VERSION ""

NS_ :

BS_:

BU_:
VAL_TABLE_ ActiveStored 1 "Active" 0 "Stored" ;
VAL_TABLE_ LN 63 "ACM" 53 "4WS" 51 "EFC" 33 "PICTO" 32 "CEAG" 31 "EMM" 30 "SPECIFIC" 27 "TA" 26 "SBL" 25 "WBZ" 24 "SCT" 20 "INFO" 17 "LCP" 15 "ZE" 13 "TELEM" 12 "DIAGNOSE" 11 "TI" 4 "DRIVE" 3 "MFA" 2 "NT01" 1 "ES" 0 "DASH" ;
VAL_TABLE_ DiagFlag 1 "Active" 0 "Not Active" ;
VAL_TABLE_ RequestID 49 "Counters and Env Vars" 23 "Read Error Memory" 20 "Clear Error Memory" ;

BO_ 3221225472 VECTOR__INDEPENDENT_SIG_MSG: 0 Vector__XXX
 SG_ Time : 0|32@1+ (1,0) [0|0] "" Vector__XXX
 SG_ Date : 0|32@1+ (1,0) [0|0] "" Vector__XXX
 SG_ OperatingHours : 0|32@1+ (1,0) [0|0] "" Vector__XXX

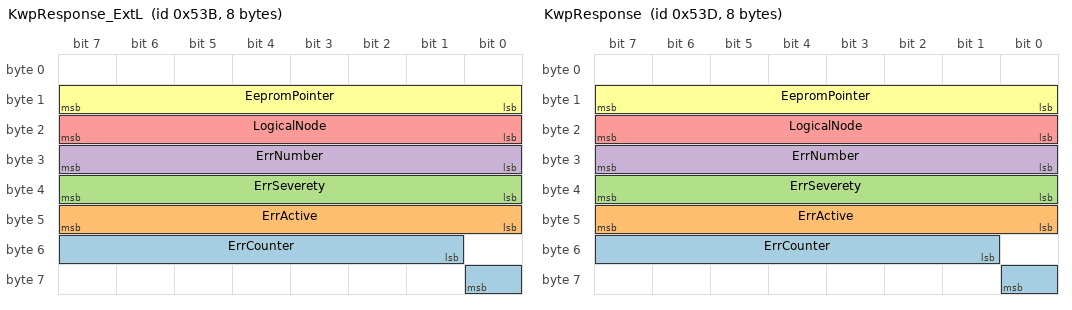
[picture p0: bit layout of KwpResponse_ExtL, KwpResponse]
BO_ 1339 KwpResponse_ExtL: 8 Vector__XXX
 SG_ ErrCounter : 49|8@1+ (1,0) [0|0] "" Vector__XXX
 SG_ ErrActive : 40|8@1+ (1,0) [0|0] "" Vector__XXX
 SG_ ErrSeverety : 32|8@1+ (1,0) [0|0] "" Vector__XXX
 SG_ ErrNumber : 24|8@1+ (1,0) [0|0] "" Vector__XXX
 SG_ LogicalNode : 16|8@1+ (1,0) [0|0] "" Vector__XXX
 SG_ EepromPointer : 8|8@1+ (1,0) [0|0] "" Vector__XXX

BO_ 1338 KwpRequest_ExtL: 4 Vector__XXX
 SG_ DiagMode : 24|8@1+ (1,0) [0|0] "" Vector__XXX
 SG_ RequestID : 8|8@1+ (1,0) [0|0] "" Vector__XXX

BO_ 1341 KwpResponse: 8 Vector__XXX
 SG_ ErrCounter : 49|8@1+ (1,0) [0|0] "" Vector__XXX
 SG_ ErrActive : 40|8@1+ (1,0) [0|0] "" Vector__XXX
 SG_ ErrSeverety : 32|8@1+ (1,0) [0|0] "" Vector__XXX
 SG_ ErrNumber : 24|8@1+ (1,0) [0|0] "" Vector__XXX
 SG_ LogicalNode : 16|8@1+ (1,0) [0|0] "" Vector__XXX
 SG_ EepromPointer : 8|8@1+ (1,0) [0|0] "" Vector__XXX

BO_ 1340 KwpRequest: 4 Vector__XXX
 SG_ DiagMode : 24|8@1+ (1,0) [0|0] "" Vector__XXX
 SG_ RequestID : 8|8@1+ (1,0) [0|0] "" Vector__XXX

CM_ BO_ 3221225472 "This is a message for not used signals, created by Vector CANdb++ DBC OLE DB Provider.";
BA_DEF_ SG_  "SigType" ENUM  "Default","Range","RangeSigned","ASCII","Discrete","Control","ReferencePGN","DTC","StringDelimiter","StringLength","StringLengthControl","MessageCounter","MessageChecksum";
BA_DEF_ SG_  "GenSigEVName" STRING ;
BA_DEF_ SG_  "GenSigILSupport" ENUM  "No","Yes";
BA_DEF_ SG_  "GenSigSendType" ENUM  "Cyclic","OnWrite","OnWriteWithRepetition","OnChange","OnChangeWithRepetition","IfActive","IfActiveWithRepetition","NoSigSendType";
BA_DEF_ BO_  "GenMsgILSupport" ENUM  "No","Yes";
BA_DEF_ BU_  "NmStationAddress" INT 0 255;
BA_DEF_ BO_  "GenMsgSendType" ENUM  "cyclic","NotUsed","IfActive","NotUsed","NotUsed","NotUsed","NotUsed","NotUsed","noMsgSendType";
BA_DEF_ BO_  "GenMsgRequestable" INT 0 1;
BA_DEF_  "DBName" STRING ;
BA_DEF_  "BusType" STRING ;
BA_DEF_  "ProtocolType" STRING ;
BA_DEF_ BO_  "VFrameFormat" ENUM  "StandardCAN","ExtendedCAN","reserved","J1939PG";
BA_DEF_DEF_  "SigType" "Default";
BA_DEF_DEF_  "GenSigEVName" "Env@Nodename_@Signame";
BA_DEF_DEF_  "GenSigILSupport" "Yes";
BA_DEF_DEF_  "GenSigSendType" "NoSigSendType";
BA_DEF_DEF_  "GenMsgILSupport" "Yes";
BA_DEF_DEF_  "NmStationAddress" 254;
BA_DEF_DEF_  "GenMsgSendType" "noMsgSendType";
BA_DEF_DEF_  "GenMsgRequestable" 1;
BA_DEF_DEF_  "DBName" "";
BA_DEF_DEF_  "BusType" "CAN";
BA_DEF_DEF_  "ProtocolType" "J1939";
BA_DEF_DEF_  "VFrameFormat" "J1939PG";
BA_ "DBName" "KWP";
BA_ "VFrameFormat" BO_ 1339 0;
BA_ "VFrameFormat" BO_ 1338 0;
BA_ "VFrameFormat" BO_ 1341 0;
BA_ "VFrameFormat" BO_ 1340 0;
VAL_ 1339 ErrActive 1 "Active" 0 "Stored" ;
VAL_ 1339 LogicalNode 63 "ACM" 53 "4WS" 51 "EFC" 33 "PICTO" 32 "CEAG" 31 "EMM" 30 "SPECIFIC" 27 "TA" 26 "SBL" 25 "WBZ" 24 "SCT" 20 "INFO" 17 "LCP" 15 "ZE" 13 "TELEM" 12 "DIAGNOSE" 11 "TI" 4 "DRIVE" 3 "MFA" 2 "NT01" 1 "ES" 0 "DASH" ;
VAL_ 1338 DiagMode 1 "Active" 0 "Not Active" ;
VAL_ 1338 RequestID 49 "Counters and Env Vars" 23 "Read Error Memory" 20 "Clear Error Memory" ;
VAL_ 1341 ErrActive 1 "Active" 0 "Stored" ;
VAL_ 1341 LogicalNode 63 "ACM" 53 "4WS" 51 "EFC" 33 "PICTO" 32 "CEAG" 31 "EMM" 30 "SPECIFIC" 27 "TA" 26 "SBL" 25 "WBZ" 24 "SCT" 20 "INFO" 17 "LCP" 15 "ZE" 13 "TELEM" 12 "DIAGNOSE" 11 "TI" 4 "DRIVE" 3 "MFA" 2 "NT01" 1 "ES" 0 "DASH" ;
VAL_ 1340 DiagMode 1 "Active" 0 "Not Active" ;
VAL_ 1340 RequestID 49 "Counters and Env Vars" 23 "Read Error Memory" 20 "Clear Error Memory" ;
